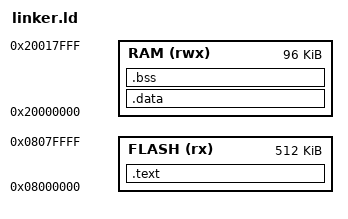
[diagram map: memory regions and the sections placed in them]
MEMORY
{
  FLASH (rx)  : ORIGIN = 0x08000000, LENGTH = 512K
  RAM   (rwx) : ORIGIN = 0x20000000, LENGTH = 96K
}

SECTIONS {
  .text : {
    KEEP(*(.isr_vector))   /* interrupt vector table */
    *(.text*)
    *(.rodata*)
  } > FLASH

  .data : AT (ADDR(.text) + SIZEOF(.text)) {
    _sdata = .;
    *(.data*)
    _edata = .;
  } > RAM

  .bss : {
    _sbss = .;
    *(.bss*)
    *(COMMON)
    _ebss = .;
  } > RAM

  _sidata = LOADADDR(.data);
  _estack = ORIGIN(RAM) + LENGTH(RAM);
}
